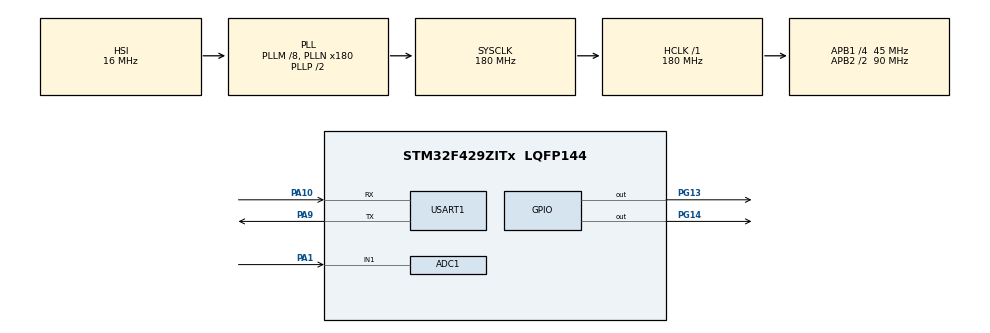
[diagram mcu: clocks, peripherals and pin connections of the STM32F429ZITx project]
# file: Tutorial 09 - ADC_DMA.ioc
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ADC1.Channel-10\#ChannelRegularConversion=ADC_CHANNEL_1
ADC1.Channel-11\#ChannelRegularConversion=ADC_CHANNEL_1
ADC1.Channel-3\#ChannelRegularConversion=ADC_CHANNEL_1
ADC1.Channel-9\#ChannelRegularConversion=ADC_CHANNEL_1
ADC1.ContinuousConvMode=ENABLE
ADC1.DMAContinuousRequests=ENABLE
ADC1.NbrOfConversion=4
ADC1.NbrOfConversionFlag=1
ADC1.Rank-10\#ChannelRegularConversion=3
ADC1.Rank-11\#ChannelRegularConversion=4
ADC1.Rank-3\#ChannelRegularConversion=1
ADC1.Rank-9\#ChannelRegularConversion=2
ADC1.SamplingTime-10\#ChannelRegularConversion=ADC_SAMPLETIME_56CYCLES
ADC1.SamplingTime-11\#ChannelRegularConversion=ADC_SAMPLETIME_84CYCLES
ADC1.SamplingTime-3\#ChannelRegularConversion=ADC_SAMPLETIME_15CYCLES
ADC1.SamplingTime-9\#ChannelRegularConversion=ADC_SAMPLETIME_28CYCLES
ADC1.master=1
Dma.ADC1.0.Direction=DMA_PERIPH_TO_MEMORY
Dma.ADC1.0.FIFOMode=DMA_FIFOMODE_DISABLE
Dma.ADC1.0.Instance=DMA2_Stream0
Dma.ADC1.0.MemDataAlignment=DMA_MDATAALIGN_HALFWORD
Dma.ADC1.0.MemInc=DMA_MINC_ENABLE
Dma.ADC1.0.Mode=DMA_CIRCULAR
Dma.ADC1.0.PeriphDataAlignment=DMA_PDATAALIGN_HALFWORD
Dma.ADC1.0.PeriphInc=DMA_PINC_DISABLE
Dma.ADC1.0.Priority=DMA_PRIORITY_LOW
Dma.Request0=ADC1
Mcu.Family=STM32F4
Mcu.Name=STM32F429ZITx
Mcu.Package=LQFP144
NVIC.DMA2_Stream0_IRQn=true\:0\:0\:false\:false\:true\:false\:true
NVIC.PriorityGroup=NVIC_PRIORITYGROUP_4
NVIC.USART1_IRQn=true\:0\:0\:false\:false\:true\:true\:true
PA1.Signal=ADCx_IN1
PA10.Mode=Asynchronous
PA10.Signal=USART1_RX
PA9.Mode=Asynchronous
PA9.Signal=USART1_TX
PG13.Signal=GPIO_Output
PG14.Signal=GPIO_Output
PH0/OSC_IN.Mode=HSE-External-Oscillator
PH0/OSC_IN.Signal=RCC_OSC_IN
PH1/OSC_OUT.Mode=HSE-External-Oscillator
PH1/OSC_OUT.Signal=RCC_OSC_OUT
ProjectManager.HeapSize=0x200
ProjectManager.StackSize=0x400
ProjectManager.TargetToolchain=STM32CubeIDE
RCC.48MHZClocksFreq_Value=90000000
RCC.AHBFreq_Value=180000000
RCC.APB1CLKDivider=RCC_HCLK_DIV4
RCC.APB1Freq_Value=45000000
RCC.APB1TimFreq_Value=90000000
RCC.APB2CLKDivider=RCC_HCLK_DIV2
RCC.APB2Freq_Value=90000000
RCC.APB2TimFreq_Value=180000000
RCC.CortexFreq_Value=180000000
RCC.HCLKFreq_Value=180000000
RCC.HSE_VALUE=8000000
RCC.HSI_VALUE=16000000
RCC.LSE_VALUE=32768
RCC.PLLM=8
RCC.PLLN=180
RCC.SYSCLKFreq_VALUE=180000000
RCC.SYSCLKSource=RCC_SYSCLKSOURCE_PLLCLK
RCC.VCOOutputFreq_Value=360000000
SH.ADCx_IN1.0=ADC1_IN1,IN1
USART1.VirtualMode=VM_ASYNC
board=custom

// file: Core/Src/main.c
/* USER CODE BEGIN Header */
/**
  ******************************************************************************
  * @file           : main.c
  * @brief          : Main program body
  ******************************************************************************
  * @attention
  *
  * <h2><center>&copy; Copyright (c) 2021 STMicroelectronics.
  * All rights reserved.</center></h2>
  *
  * This software component is licensed by ST under BSD 3-Clause license,
  * the "License"; You may not use this file except in compliance with the
  * License. You may obtain a copy of the License at:
  *                        opensource.org/licenses/BSD-3-Clause
  *
  ******************************************************************************
  */
/* USER CODE END Header */
#include "main.h"
#include "adc.h"
#include "dma.h"
#include "usart.h"
#include "gpio.h"

/* USER CODE BEGIN Includes */
#include "utility.h"
/* USER CODE END Includes */

/* USER CODE BEGIN PV */
uint8_t rxData;

uint16_t adcval[4];

/* USER CODE END PV */

void SystemClock_Config(void);
/* USER CODE BEGIN PFP */
int _write(int file, char *ptr, int len)
{
  HAL_UART_Transmit(&huart1, (uint8_t *)ptr, len, 10);
  return len;
}
/* USER CODE END PFP */

int main(void)
{

  /* MCU Configuration--------------------------------------------------------*/

  /* Reset of all peripherals, Initializes the Flash interface and the Systick. */
  HAL_Init();

  /* Configure the system clock */
  SystemClock_Config();

  /* Initialize all configured peripherals */
  MX_GPIO_Init();
  MX_USART1_UART_Init();
  MX_DMA_Init();
  MX_ADC1_Init();
  /* USER CODE BEGIN 2 */

  HAL_ADC_Start_DMA(&hadc1, &adcval[0], 4);

  /* USER CODE END 2 */

  /* Infinite loop */
  /* USER CODE BEGIN WHILE */

  while (1)
  {
    printf("%4d, %4d, %4d, %4d\n\r", adcval[0], adcval[1], adcval[2], adcval[3]);

    HAL_Delay(1000);

    /* USER CODE END WHILE */

  }
}

void SystemClock_Config(void)
{
  RCC_OscInitTypeDef RCC_OscInitStruct = {0};
  RCC_ClkInitTypeDef RCC_ClkInitStruct = {0};

  /** Configure the main internal regulator output voltage
  */
  __HAL_RCC_PWR_CLK_ENABLE();
  __HAL_PWR_VOLTAGESCALING_CONFIG(PWR_REGULATOR_VOLTAGE_SCALE1);
  /** Initializes the RCC Oscillators according to the specified parameters
  * in the RCC_OscInitTypeDef structure.
  */
  RCC_OscInitStruct.OscillatorType = RCC_OSCILLATORTYPE_HSI;
  RCC_OscInitStruct.HSIState = RCC_HSI_ON;
  RCC_OscInitStruct.HSICalibrationValue = RCC_HSICALIBRATION_DEFAULT;
  RCC_OscInitStruct.PLL.PLLState = RCC_PLL_ON;
  RCC_OscInitStruct.PLL.PLLSource = RCC_PLLSOURCE_HSI;
  RCC_OscInitStruct.PLL.PLLM = 8;
  RCC_OscInitStruct.PLL.PLLN = 180;
  RCC_OscInitStruct.PLL.PLLP = RCC_PLLP_DIV2;
  RCC_OscInitStruct.PLL.PLLQ = 4;
  if (HAL_RCC_OscConfig(&RCC_OscInitStruct) != HAL_OK)
  {
    Error_Handler();
  }
  /** Activate the Over-Drive mode
  */
  if (HAL_PWREx_EnableOverDrive() != HAL_OK)
  {
    Error_Handler();
  }
  /** Initializes the CPU, AHB and APB buses clocks
  */
  RCC_ClkInitStruct.ClockType = RCC_CLOCKTYPE_HCLK|RCC_CLOCKTYPE_SYSCLK
                              |RCC_CLOCKTYPE_PCLK1|RCC_CLOCKTYPE_PCLK2;
  RCC_ClkInitStruct.SYSCLKSource = RCC_SYSCLKSOURCE_PLLCLK;
  RCC_ClkInitStruct.AHBCLKDivider = RCC_SYSCLK_DIV1;
  RCC_ClkInitStruct.APB1CLKDivider = RCC_HCLK_DIV4;
  RCC_ClkInitStruct.APB2CLKDivider = RCC_HCLK_DIV2;

  if (HAL_RCC_ClockConfig(&RCC_ClkInitStruct, FLASH_LATENCY_5) != HAL_OK)
  {
    Error_Handler();
  }
}

/* USER CODE BEGIN 4 */

void HAL_UART_RxCpltCallback(UART_HandleTypeDef *huart)
{
  if (huart->Instance == USART1)
  {
    HAL_UART_Receive_IT(&huart1, &rxData, 1);
    HAL_UART_Transmit(&huart1, &rxData, 1, 10);
  }
}

/* USER CODE END 4 */

void Error_Handler(void)
{
  __disable_irq();
  while (1)
  {
  }
}

/************************ (C) COPYRIGHT STMicroelectronics *****END OF FILE****/
